# TMS320F280049 register map
Vendor: Texas Instruments; Series: C2000 F28004x; File version: 0.2.0-generated
Registers are 16-bit, read-write, reset 0x0 unless marked. A register's access mark holds for its fields unless they carry their own. Offsets are from the block's base; [hi:lo] are bit positions; {n}, {i} and the like mark numbered series.

## I2CAREGS — I2C Registers
Base 0x0000E600
0x00 I2COAR — I2C Own address
  [15:9] OAR
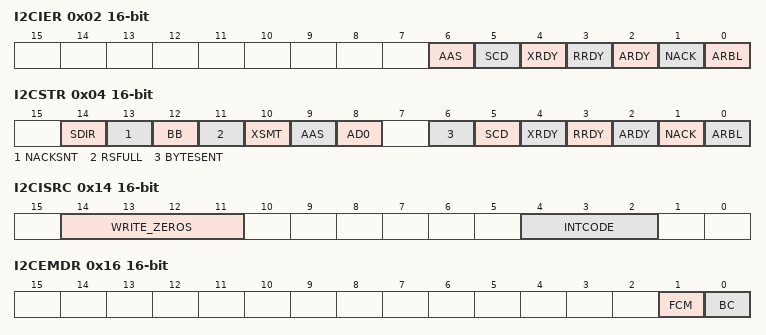
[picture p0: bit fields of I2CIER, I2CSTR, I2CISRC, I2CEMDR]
0x02 I2CIER — I2C Interrupt Enable
  [6] AAS — Addressed as slave interrupt enable
  [5] SCD — Stop condition detected interrupt enable
  [4] XRDY — Transmit-data-ready interrupt enable
  [3] RRDY — Receive-data-ready interrupt enable
  [2] ARDY — Register-access-ready interrupt enable
  [1] NACK — No-acknowledgment interrupt enable
  [0] ARBL — Arbitration-lost interrupt enable
0x04 I2CSTR — I2C Status
  [14] SDIR — Slave direction bit
  [13] NACKSNT — NACK sent bit.
  [12] BB — Bus busy bit.
  [11] RSFULL — Receive shift register full bit.
  [10] XSMT — Transmit shift register empty bit.
  [9] AAS — Addressed-as-slave bit
  [8] AD0 — Address 0 bits
  [6] BYTESENT — Byte transmit over indication
  [5] SCD — Stop condition detected bit.
  [4] XRDY — Transmit-data-ready interrupt flag bit.
  [3] RRDY — Receive-data-ready interrupt flag bit.
  [2] ARDY — Register-access-ready interrupt flag bit
  [1] NACK — No-acknowledgment interrupt flag bit.
  [0] ARBL — Arbitration-lost interrupt flag bit
0x06 I2CCLKL — I2C Clock low-time divider
  [15] I2CCLKL — Clock low-time divide-down value.
0x08 I2CCLKH — I2C Clock high-time divider
  [15] I2CCLKH — Clock high-time divide-down value.
0x0A I2CCNT — I2C Data count
  [15] I2CCNT — Data count value.
0x0C I2CDRR — I2C Data receive
  [14:7] DATA — Receive data
0x0E I2CSAR — I2C Slave address
  [15:9] SAR — Slave Address
0x10 I2CDXR — I2C Data Transmit
  [14:7] DATA — Transmit data
0x12 I2CMDR — I2C Mode
  [15] NACKMOD — NACK mode bit
  [14] FREE — Debug Action
  [13] STT — START condition bit
  [11] STP — STOP Condition
  [10] MST — Master Mode
  [9] TRX — Transmitter Mode
  [8] XA — Expanded Address Mode
  [7] RM — Repeat Mode
  [6] DLB — Digital Loopback Mode
  [5] IRS — I2C Module Reset
  [4] STB — START Byte Mode
  [3] FDF — Free Data Format
  [4:2] BC — Bit count bits.
0x14 I2CISRC — I2C Interrupt Source
  [14:11] WRITE_ZEROS — Always write all 0s to this field
  [4:2] INTCODE — Interrupt code bits.
0x16 I2CEMDR — I2C Extended Mode
  [1] FCM — Forward Compatibility for Tx behav in Type1
  [0] BC — Backwards compatibility mode
0x18 I2CPSC — I2C Prescaler
  [14:7] IPSC — I2C Prescaler Divide Down
0x40 I2CFFTX — I2C FIFO Transmit
  [14] I2CFFEN — Transmit FIFO Enable
  [13] TXFFRST — Transmit FIFO Reset
  [15:12] TXFFST — Transmit FIFO Status
  [7] TXFFINT — Transmit FIFO Interrupt Flag
  [6] TXFFINTCLR — Transmit FIFO Interrupt Flag Clear
  [5] TXFFIENA — Transmit FIFO Interrupt Enable
  [8:4] TXFFIL — Transmit FIFO Interrupt Level
0x42 I2CFFRX — I2C FIFO Receive
  [13] RXFFRST — Receive FIFO Reset
  [15:12] RXFFST — Receive FIFO Status
  [7] RXFFINT — Receive FIFO Interrupt Flag
  [6] RXFFINTCLR — Receive FIFO Interrupt Flag Clear
  [5] RXFFIENA — Receive FIFO Interrupt Enable
  [8:4] RXFFIL — Receive FIFO Interrupt Level

## INPUTXBARREGS — INPUT XBAR Registers
Base 0x0000F200
0x00 INPUT1SELECT — INPUT1 Input Select Register (GPIO0 to x)
  [15] SELECT — Select GPIO for INPUT1 signal
0x02 INPUT2SELECT — INPUT2 Input Select Register (GPIO0 to x)
  [15] SELECT — Select GPIO for INPUT2 signal
0x04 INPUT3SELECT — INPUT3 Input Select Register (GPIO0 to x)
  [15] SELECT — Select GPIO for INPUT3 signal
0x06 INPUT4SELECT — INPUT4 Input Select Register (GPIO0 to x)
  [15] SELECT — Select GPIO for INPUT4 signal
0x08 INPUT5SELECT — INPUT5 Input Select Register (GPIO0 to x)
  [15] SELECT — Select GPIO for INPUT5 signal
0x0A INPUT6SELECT — INPUT6 Input Select Register (GPIO0 to x)
  [15] SELECT — Select GPIO for INPUT6 signal
0x0C INPUT7SELECT — INPUT7 Input Select Register (GPIO0 to x)
  [15] SELECT — Select GPIO for INPUT7 signal
0x0E INPUT8SELECT — INPUT8 Input Select Register (GPIO0 to x)
  [15] SELECT — Select GPIO for INPUT8 signal
0x10 INPUT9SELECT — INPUT9 Input Select Register (GPIO0 to x)
  [15] SELECT — Select GPIO for INPUT9 signal
0x12 INPUT10SELECT — INPUT10 Input Select Register (GPIO0 to x)
  [15] SELECT — Select GPIO for INPUT10 signal
0x14 INPUT11SELECT — INPUT11 Input Select Register (GPIO0 to x)
  [15] SELECT — Select GPIO for INPUT11 signal
0x16 INPUT12SELECT — INPUT12 Input Select Register (GPIO0 to x)
  [15] SELECT — Select GPIO for INPUT12 signal
0x18 INPUT13SELECT — INPUT13 Input Select Register (GPIO0 to x)
  [15] SELECT — Select GPIO for INPUT13 signal
0x1A INPUT14SELECT — INPUT14 Input Select Register (GPIO0 to x)
  [15] SELECT — Select GPIO for INPUT14 signal
0x1C INPUT15SELECT — INPUT15 Input Select Register (GPIO0 to x)
  [15] SELECT — Select GPIO for INPUT15 signal
0x1E INPUT16SELECT — INPUT16 Input Select Register (GPIO0 to x)
  [15] SELECT — Select GPIO for INPUT16 signal
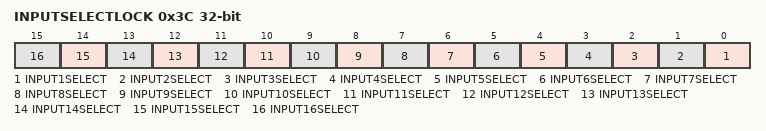
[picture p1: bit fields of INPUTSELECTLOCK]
0x3C INPUTSELECTLOCK 32-bit
  [n-1] INPUT{n}SELECT (n=1..16) — Lock bit for INPUT{n}SELECT Register
